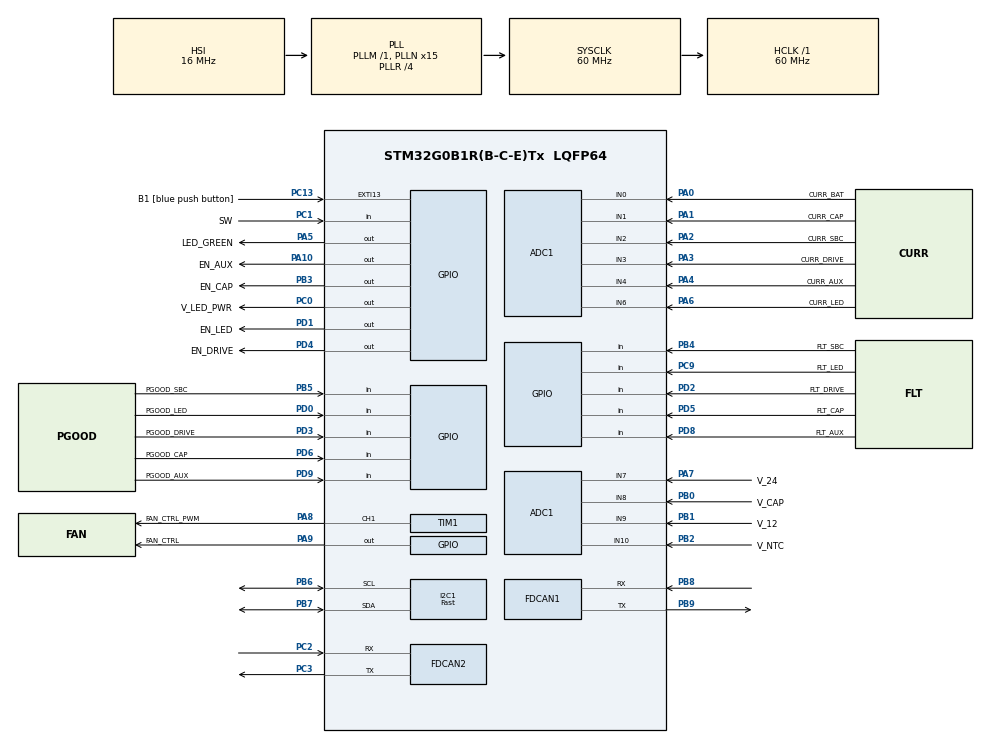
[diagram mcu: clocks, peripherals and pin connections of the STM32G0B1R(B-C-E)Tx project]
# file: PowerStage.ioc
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ADC1.ClockPrescaler=ADC_CLOCK_SYNC_PCLK_DIV4
ADC1.ContinuousConvMode=ENABLE
ADC1.DMAContinuousRequests=ENABLE
ADC1.EOCSelection=ADC_EOC_SEQ_CONV
ADC1.NbrOfConversion=1
ADC1.NbrOfConversionFlag=0
ADC1.Overrun=ADC_OVR_DATA_OVERWRITTEN
ADC1.SamplingTimeCommon1=ADC_SAMPLETIME_19CYCLES_5
ADC1.SelectedChannel=ADC_CHANNEL_0|ADC_CHANNEL_1|ADC_CHANNEL_2|ADC_CHANNEL_3|ADC_CHANNEL_4|ADC_CHANNEL_6|ADC_CHANNEL_7|ADC_CHANNEL_8|ADC_CHANNEL_9|ADC_CHANNEL_10
ADC1.Sequencer=NOT_FULLY_CONFIGURABLE
ADC1.master=1
Dma.ADC1.0.Direction=DMA_PERIPH_TO_MEMORY
Dma.ADC1.0.EventEnable=DISABLE
Dma.ADC1.0.Instance=DMA1_Channel1
Dma.ADC1.0.MemDataAlignment=DMA_MDATAALIGN_WORD
Dma.ADC1.0.MemInc=DMA_MINC_ENABLE
Dma.ADC1.0.Mode=DMA_CIRCULAR
Dma.ADC1.0.PeriphDataAlignment=DMA_PDATAALIGN_WORD
Dma.ADC1.0.PeriphInc=DMA_PINC_DISABLE
Dma.ADC1.0.Polarity=HAL_DMAMUX_REQ_GEN_RISING
Dma.ADC1.0.Priority=DMA_PRIORITY_LOW
Dma.ADC1.0.RequestNumber=1
Dma.ADC1.0.SignalID=NONE
Dma.ADC1.0.SyncEnable=DISABLE
Dma.ADC1.0.SyncPolarity=HAL_DMAMUX_SYNC_NO_EVENT
Dma.ADC1.0.SyncRequestNumber=1
Dma.ADC1.0.SyncSignalID=NONE
Dma.Request0=ADC1
FDCAN1.AutoRetransmission=ENABLE
FDCAN1.CalculateBaudRateNominal=500000
FDCAN1.CalculateTimeBitNominal=2000
FDCAN1.CalculateTimeQuantumNominal=100.0
FDCAN1.ClockDivider=FDCAN_CLOCK_DIV1
FDCAN1.DataPrescaler=1
FDCAN1.DataTimeSeg2=1
FDCAN1.ExtFiltersNbr=2
FDCAN1.NominalPrescaler=6
FDCAN1.NominalSyncJumpWidth=4
FDCAN1.NominalTimeSeg1=16
FDCAN1.NominalTimeSeg2=3
FDCAN1.StdFiltersNbr=2
FDCAN2.AutoRetransmission=ENABLE
FDCAN2.CalculateBaudRateNominal=500000
FDCAN2.CalculateTimeBitNominal=2000
FDCAN2.CalculateTimeQuantumNominal=100.0
FDCAN2.NominalPrescaler=6
FDCAN2.NominalSyncJumpWidth=4
FDCAN2.NominalTimeSeg1=16
FDCAN2.NominalTimeSeg2=3
FDCAN2.StdFiltersNbr=2
I2C1.CustomTiming=Enabled
I2C1.GeneralCallMode=I2C_GENERALCALL_DISABLE
I2C1.I2C_Speed_Mode=I2C_Fast
I2C1.Timing=0x00503D58
Mcu.Family=STM32G0
Mcu.Name=STM32G0B1R(B-C-E)Tx
Mcu.Package=LQFP64
NVIC.TIM16_FDCAN_IT0_IRQn=true\:0\:0\:false\:false\:true\:true\:true\:true
PA0.GPIO_Label=CURR_BAT
PA0.Mode=IN0
PA0.Signal=ADC1_IN0
PA1.GPIO_Label=CURR_CAP
PA1.Mode=IN1
PA1.Signal=ADC1_IN1
PA10.GPIO_Label=EN_AUX
PA10.Signal=GPIO_Output
PA13.GPIO_Label=TMS
PA13.Mode=Serial_Wire
PA13.Signal=SYS_SWDIO
PA14-BOOT0.GPIO_Label=TCK
PA14-BOOT0.Mode=Serial_Wire
PA14-BOOT0.Signal=SYS_SWCLK
PA2.GPIO_Label=CURR_SBC
PA2.Mode=IN2
PA2.Signal=ADC1_IN2
PA3.GPIO_Label=CURR_DRIVE
PA3.Mode=IN3
PA3.Signal=ADC1_IN3
PA4.GPIO_Label=CURR_AUX
PA4.Mode=IN4
PA4.Signal=ADC1_IN4
PA5.GPIO_Label=LED_GREEN
PA5.GPIO_Speed=GPIO_SPEED_FREQ_HIGH
PA5.Signal=GPIO_Output
PA6.GPIO_Label=CURR_LED
PA6.Mode=IN6
PA6.Signal=ADC1_IN6
PA7.GPIO_Label=V_24
PA7.Mode=IN7
PA7.Signal=ADC1_IN7
PA8.GPIO_Label=FAN_CTRL_PWM
PA8.PinState=GPIO_PIN_RESET
PA8.Signal=S_TIM1_CH1
PA9.GPIO_Label=FAN_CTRL
PA9.Signal=GPIO_Output
PB0.GPIO_Label=V_CAP
PB0.Mode=IN8
PB0.Signal=ADC1_IN8
PB1.GPIO_Label=V_12
PB1.Mode=IN9
PB1.Signal=ADC1_IN9
PB2.GPIO_Label=V_NTC
PB2.Mode=IN10
PB2.Signal=ADC1_IN10
PB3.GPIO_Label=EN_CAP
PB3.Signal=GPIO_Output
PB4.GPIO_Label=FLT_SBC
PB4.GPIO_PuPd=GPIO_PULLUP
PB4.Signal=GPIO_Input
PB5.GPIO_Label=PGOOD_SBC
PB5.GPIO_PuPd=GPIO_PULLUP
PB5.Signal=GPIO_Input
PB6.GPIO_Pu=GPIO_PULLUP
PB6.Mode=I2C
PB6.Signal=I2C1_SCL
PB7.GPIO_Pu=GPIO_PULLUP
PB7.Mode=I2C
PB7.Signal=I2C1_SDA
PB8.GPIO_PuPd=GPIO_PULLUP
PB8.Mode=FDCAN_Activate
PB8.Signal=FDCAN1_RX
PB9.GPIO_PuPd=GPIO_PULLUP
PB9.Mode=FDCAN_Activate
PB9.Signal=FDCAN1_TX
PC0.GPIO_Label=V_LED_PWR
PC0.Signal=GPIO_Output
PC1.GPIO_Label=SW
PC1.GPIO_PuPd=GPIO_PULLUP
PC1.Signal=GPIO_Input
PC13.GPIO_Label=B1 [blue push button]
PC13.Signal=GPXTI13
PC14-OSC32_IN\ (PC14).Mode=LSE-External-Oscillator
PC14-OSC32_IN\ (PC14).Signal=RCC_OSC32_IN
PC15-OSC32_OUT\ (PC15).Mode=LSE-External-Oscillator
PC15-OSC32_OUT\ (PC15).Signal=RCC_OSC32_OUT
PC2.GPIO_PuPd=GPIO_PULLUP
PC2.Mode=FDCAN_Activate
PC2.Signal=FDCAN2_RX
PC3.Mode=FDCAN_Activate
PC3.Signal=FDCAN2_TX
PC9.GPIO_Label=FLT_LED
PC9.GPIO_PuPd=GPIO_PULLUP
PC9.Signal=GPIO_Input
PD0.GPIO_Label=PGOOD_LED
PD0.GPIO_PuPd=GPIO_PULLUP
PD0.Signal=GPIO_Input
PD1.GPIO_Label=EN_LED
PD1.Signal=GPIO_Output
PD2.GPIO_Label=FLT_DRIVE
PD2.GPIO_PuPd=GPIO_PULLUP
PD2.Signal=GPIO_Input
PD3.GPIO_Label=PGOOD_DRIVE
PD3.GPIO_PuPd=GPIO_PULLUP
PD3.Signal=GPIO_Input
PD4.GPIO_Label=EN_DRIVE
PD4.Signal=GPIO_Output
PD5.GPIO_Label=FLT_CAP
PD5.GPIO_PuPd=GPIO_PULLUP
PD5.Signal=GPIO_Input
PD6.GPIO_Label=PGOOD_CAP
PD6.GPIO_PuPd=GPIO_PULLUP
PD6.Signal=GPIO_Input
PD8.GPIO_Label=FLT_AUX
PD8.GPIO_PuPd=GPIO_PULLUP
PD8.Signal=GPIO_Input
PD9.GPIO_Label=PGOOD_AUX
PD9.GPIO_PuPd=GPIO_PULLUP
PD9.Signal=GPIO_Input
PF0-OSC_IN\ (PF0).Mode=HSE-External-Oscillator
PF0-OSC_IN\ (PF0).Signal=RCC_OSC_IN
PF1-OSC_OUT\ (PF1).Mode=HSE-External-Oscillator
PF1-OSC_OUT\ (PF1).Signal=RCC_OSC_OUT
ProjectManager.HeapSize=0x200
ProjectManager.StackSize=0x400
ProjectManager.TargetToolchain=STM32CubeIDE
RCC.ADCFreq_Value=60000000
RCC.AHBFreq_Value=60000000
RCC.CortexFreq_Value=60000000
RCC.EXTERNAL_CLOCK_VALUE=12288000
RCC.HCLKFreq_Value=60000000
RCC.HSE_VALUE=8000000
RCC.HSI48_VALUE=48000000
RCC.HSI_VALUE=16000000
RCC.PLLN=15
RCC.PLLR=RCC_PLLR_DIV4
RCC.SYSCLKFreq_VALUE=60000000
RCC.SYSCLKSource=RCC_SYSCLKSOURCE_PLLCLK
RCC.USBFreq_Value=48000000
RCC.VCOOutputFreq_Value=240000000
SH.S_TIM1_CH1.0=TIM1_CH1,PWM Generation1 CH1
TIM1.AutoReloadPreload=TIM_AUTORELOAD_PRELOAD_ENABLE
TIM1.Channel-PWM\ Generation1\ CH1=TIM_CHANNEL_1
TIM1.OCIdleState_1=TIM_OCIDLESTATE_RESET
TIM1.OCPolarity_1=TIM_OCPOLARITY_HIGH
TIM1.Period=999
TIM1.Prescaler=59
TIM1.Pulse-PWM\ Generation1\ CH1=100
VP_SYS_VS_DBSignals.Mode=DisableDeadBatterySignals
VP_TIM1_VS_ClockSourceINT.Mode=Internal
board=NUCLEO-G0B1RE

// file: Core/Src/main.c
/* USER CODE BEGIN Header */
/**
  ******************************************************************************
  * @file           : main.c
  * @brief          : Main program body
  ******************************************************************************
  * @attention
  *
  * Copyright (c) 2026 STMicroelectronics.
  * All rights reserved.
  *
  * This software is licensed under terms that can be found in the LICENSE file
  * in the root directory of this software component.
  * If no LICENSE file comes with this software, it is provided AS-IS.
  *
  ******************************************************************************
  */
/* USER CODE END Header */
#include "main.h"

/* USER CODE BEGIN Includes */

#include "powerstage_app.h"
#include "io_module.h"
/* USER CODE END Includes */

/* USER CODE BEGIN PTD */

/**
  * @brief  Vector base address configuration. It should no longer be at the start of
  *         flash memory but moved forward because the first part of flash is
  *         reserved for the bootloader. Note that this is already done by the
  *         bootloader before starting this program. Unfortunately, function
  *         SystemInit() overwrites this change again.
  * @return none.
  */
static void VectorBase_Config(void)
{
  /* The constant array with vectors of the vector table is declared externally in the
   * c-startup code.
   */
  extern const unsigned long g_pfnVectors[];

  /* Remap the vector table to where the vector table is located for this program. */
  SCB->VTOR = (unsigned long)&g_pfnVectors[0];
}
/* USER CODE END PTD */

ADC_HandleTypeDef hadc1;
DMA_HandleTypeDef hdma_adc1;

FDCAN_HandleTypeDef hfdcan1;
FDCAN_HandleTypeDef hfdcan2;

I2C_HandleTypeDef hi2c1;

TIM_HandleTypeDef htim1;

void SystemClock_Config(void);
static void MX_GPIO_Init(void);
static void MX_DMA_Init(void);
static void MX_ADC1_Init(void);
static void MX_FDCAN1_Init(void);
static void MX_FDCAN2_Init(void);
static void MX_I2C1_Init(void);
static void MX_TIM1_Init(void);

int main(void)
{

  /* USER CODE BEGIN 1 */
 VectorBase_Config();
  /* USER CODE END 1 */

  /* MCU Configuration--------------------------------------------------------*/

  /* Reset of all peripherals, Initializes the Flash interface and the Systick. */
  HAL_Init();

  /* Configure the system clock */
  SystemClock_Config();

  /* Initialize all configured peripherals */
  MX_GPIO_Init();
  MX_DMA_Init();
  MX_ADC1_Init();
  MX_FDCAN1_Init();
  MX_FDCAN2_Init();
  MX_I2C1_Init();
  MX_TIM1_Init();
  /* USER CODE BEGIN 2 */
//  AppInit();        /* OpenBLT bootloader hook */
  PS_App_Init();    /* PowerStage: CAN TX header init (full init deferred to first task call) */
  HS_DisableAll();
  /* USER CODE END 2 */

  /* Infinite loop */
  while (1)
  {

    /* USER CODE BEGIN 3 */
//    AppTask();        /* OpenBLT bootloader hook */
    PS_App_Task();    /* PowerStage state machine: Init → Running ↔ Fault */
  }
  /* USER CODE END 3 */
}

void SystemClock_Config(void)
{
  RCC_OscInitTypeDef RCC_OscInitStruct = {0};
  RCC_ClkInitTypeDef RCC_ClkInitStruct = {0};

  /** Configure the main internal regulator output voltage
  */
  HAL_PWREx_ControlVoltageScaling(PWR_REGULATOR_VOLTAGE_SCALE1);

  /** Initializes the RCC Oscillators according to the specified parameters
  * in the RCC_OscInitTypeDef structure.
  */
  RCC_OscInitStruct.OscillatorType = RCC_OSCILLATORTYPE_HSI;
  RCC_OscInitStruct.HSIState = RCC_HSI_ON;
  RCC_OscInitStruct.HSIDiv = RCC_HSI_DIV1;
  RCC_OscInitStruct.HSICalibrationValue = RCC_HSICALIBRATION_DEFAULT;
  RCC_OscInitStruct.PLL.PLLState = RCC_PLL_ON;
  RCC_OscInitStruct.PLL.PLLSource = RCC_PLLSOURCE_HSI;
  RCC_OscInitStruct.PLL.PLLM = RCC_PLLM_DIV1;
  RCC_OscInitStruct.PLL.PLLN = 15;
  RCC_OscInitStruct.PLL.PLLP = RCC_PLLP_DIV2;
  RCC_OscInitStruct.PLL.PLLQ = RCC_PLLQ_DIV2;
  RCC_OscInitStruct.PLL.PLLR = RCC_PLLR_DIV4;
  if (HAL_RCC_OscConfig(&RCC_OscInitStruct) != HAL_OK)
  {
    Error_Handler();
  }

  /** Initializes the CPU, AHB and APB buses clocks
  */
  RCC_ClkInitStruct.ClockType = RCC_CLOCKTYPE_HCLK|RCC_CLOCKTYPE_SYSCLK
                              |RCC_CLOCKTYPE_PCLK1;
  RCC_ClkInitStruct.SYSCLKSource = RCC_SYSCLKSOURCE_PLLCLK;
  RCC_ClkInitStruct.AHBCLKDivider = RCC_SYSCLK_DIV1;
  RCC_ClkInitStruct.APB1CLKDivider = RCC_HCLK_DIV1;

  if (HAL_RCC_ClockConfig(&RCC_ClkInitStruct, FLASH_LATENCY_2) != HAL_OK)
  {
    Error_Handler();
  }
}

static void MX_ADC1_Init(void)
{

  ADC_ChannelConfTypeDef sConfig = {0};

  /** Configure the global features of the ADC (Clock, Resolution, Data Alignment and number of conversion)
  */
  hadc1.Instance = ADC1;
  hadc1.Init.ClockPrescaler = ADC_CLOCK_SYNC_PCLK_DIV4;
  hadc1.Init.Resolution = ADC_RESOLUTION_12B;
  hadc1.Init.DataAlign = ADC_DATAALIGN_RIGHT;
  hadc1.Init.ScanConvMode = ADC_SCAN_SEQ_FIXED;
  hadc1.Init.EOCSelection = ADC_EOC_SEQ_CONV;
  hadc1.Init.LowPowerAutoWait = DISABLE;
  hadc1.Init.LowPowerAutoPowerOff = DISABLE;
  hadc1.Init.ContinuousConvMode = ENABLE;
  hadc1.Init.NbrOfConversion = 1;
  hadc1.Init.ExternalTrigConv = ADC_SOFTWARE_START;
  hadc1.Init.ExternalTrigConvEdge = ADC_EXTERNALTRIGCONVEDGE_NONE;
  hadc1.Init.DMAContinuousRequests = ENABLE;
  hadc1.Init.Overrun = ADC_OVR_DATA_OVERWRITTEN;
  hadc1.Init.SamplingTimeCommon1 = ADC_SAMPLETIME_19CYCLES_5;
  hadc1.Init.OversamplingMode = DISABLE;
  hadc1.Init.TriggerFrequencyMode = ADC_TRIGGER_FREQ_HIGH;
  if (HAL_ADC_Init(&hadc1) != HAL_OK)
  {
    Error_Handler();
  }

  /** Configure Regular Channel
  */
  sConfig.Channel = ADC_CHANNEL_0;
  sConfig.Rank = ADC_RANK_CHANNEL_NUMBER;
  if (HAL_ADC_ConfigChannel(&hadc1, &sConfig) != HAL_OK)
  {
    Error_Handler();
  }

  /** Configure Regular Channel
  */
  sConfig.Channel = ADC_CHANNEL_1;
  if (HAL_ADC_ConfigChannel(&hadc1, &sConfig) != HAL_OK)
  {
    Error_Handler();
  }

  /** Configure Regular Channel
  */
  sConfig.Channel = ADC_CHANNEL_2;
  if (HAL_ADC_ConfigChannel(&hadc1, &sConfig) != HAL_OK)
  {
    Error_Handler();
  }

  /** Configure Regular Channel
  */
  sConfig.Channel = ADC_CHANNEL_3;
  if (HAL_ADC_ConfigChannel(&hadc1, &sConfig) != HAL_OK)
  {
    Error_Handler();
  }

  /** Configure Regular Channel
  */
  sConfig.Channel = ADC_CHANNEL_4;
  if (HAL_ADC_ConfigChannel(&hadc1, &sConfig) != HAL_OK)
  {
    Error_Handler();
  }

  /** Configure Regular Channel
  */
  sConfig.Channel = ADC_CHANNEL_6;
  if (HAL_ADC_ConfigChannel(&hadc1, &sConfig) != HAL_OK)
  {
    Error_Handler();
  }

  /** Configure Regular Channel
  */
  sConfig.Channel = ADC_CHANNEL_7;
  if (HAL_ADC_ConfigChannel(&hadc1, &sConfig) != HAL_OK)
  {
    Error_Handler();
  }

  /** Configure Regular Channel
  */
  sConfig.Channel = ADC_CHANNEL_8;
  if (HAL_ADC_ConfigChannel(&hadc1, &sConfig) != HAL_OK)
  {
    Error_Handler();
  }

  /** Configure Regular Channel
  */
  sConfig.Channel = ADC_CHANNEL_9;
  if (HAL_ADC_ConfigChannel(&hadc1, &sConfig) != HAL_OK)
  {
    Error_Handler();
  }

  /** Configure Regular Channel
  */
  sConfig.Channel = ADC_CHANNEL_10;
  if (HAL_ADC_ConfigChannel(&hadc1, &sConfig) != HAL_OK)
  {
    Error_Handler();
  }
  /* USER CODE BEGIN ADC1_Init 2 */
  if (HAL_ADCEx_Calibration_Start(&hadc1) != HAL_OK)
  {
      Error_Handler();
  }
  /* USER CODE END ADC1_Init 2 */

}

static void MX_FDCAN1_Init(void)
{

  hfdcan1.Instance = FDCAN1;
  hfdcan1.Init.ClockDivider = FDCAN_CLOCK_DIV1;
  hfdcan1.Init.FrameFormat = FDCAN_FRAME_CLASSIC;
  hfdcan1.Init.Mode = FDCAN_MODE_NORMAL;
  hfdcan1.Init.AutoRetransmission = ENABLE;
  hfdcan1.Init.TransmitPause = DISABLE;
  hfdcan1.Init.ProtocolException = DISABLE;
  hfdcan1.Init.NominalPrescaler = 6;
  hfdcan1.Init.NominalSyncJumpWidth = 4;
  hfdcan1.Init.NominalTimeSeg1 = 16;
  hfdcan1.Init.NominalTimeSeg2 = 3;
  hfdcan1.Init.DataPrescaler = 1;
  hfdcan1.Init.DataSyncJumpWidth = 1;
  hfdcan1.Init.DataTimeSeg1 = 1;
  hfdcan1.Init.DataTimeSeg2 = 1;
  hfdcan1.Init.StdFiltersNbr = 2;
  hfdcan1.Init.ExtFiltersNbr = 2;
  hfdcan1.Init.TxFifoQueueMode = FDCAN_TX_FIFO_OPERATION;
  if (HAL_FDCAN_Init(&hfdcan1) != HAL_OK)
  {
    Error_Handler();
  }

}

static void MX_FDCAN2_Init(void)
{

  hfdcan2.Instance = FDCAN2;
  hfdcan2.Init.ClockDivider = FDCAN_CLOCK_DIV1;
  hfdcan2.Init.FrameFormat = FDCAN_FRAME_CLASSIC;
  hfdcan2.Init.Mode = FDCAN_MODE_NORMAL;
  hfdcan2.Init.AutoRetransmission = ENABLE;
  hfdcan2.Init.TransmitPause = DISABLE;
  hfdcan2.Init.ProtocolException = DISABLE;
  hfdcan2.Init.NominalPrescaler = 6;
  hfdcan2.Init.NominalSyncJumpWidth = 4;
  hfdcan2.Init.NominalTimeSeg1 = 16;
  hfdcan2.Init.NominalTimeSeg2 = 3;
  hfdcan2.Init.DataPrescaler = 1;
  hfdcan2.Init.DataSyncJumpWidth = 1;
  hfdcan2.Init.DataTimeSeg1 = 1;
  hfdcan2.Init.DataTimeSeg2 = 1;
  hfdcan2.Init.StdFiltersNbr = 2;
  hfdcan2.Init.ExtFiltersNbr = 0;
  hfdcan2.Init.TxFifoQueueMode = FDCAN_TX_FIFO_OPERATION;
  if (HAL_FDCAN_Init(&hfdcan2) != HAL_OK)
  {
    Error_Handler();
  }

}

static void MX_I2C1_Init(void)
{

  hi2c1.Instance = I2C1;
  hi2c1.Init.Timing = 0x00503D58;
  hi2c1.Init.OwnAddress1 = 0;
  hi2c1.Init.AddressingMode = I2C_ADDRESSINGMODE_7BIT;
  hi2c1.Init.DualAddressMode = I2C_DUALADDRESS_DISABLE;
  hi2c1.Init.OwnAddress2 = 0;
  hi2c1.Init.OwnAddress2Masks = I2C_OA2_NOMASK;
  hi2c1.Init.GeneralCallMode = I2C_GENERALCALL_DISABLE;
  hi2c1.Init.NoStretchMode = I2C_NOSTRETCH_DISABLE;
  if (HAL_I2C_Init(&hi2c1) != HAL_OK)
  {
    Error_Handler();
  }

  /** Configure Analogue filter
  */
  if (HAL_I2CEx_ConfigAnalogFilter(&hi2c1, I2C_ANALOGFILTER_ENABLE) != HAL_OK)
  {
    Error_Handler();
  }

  /** Configure Digital filter
  */
  if (HAL_I2CEx_ConfigDigitalFilter(&hi2c1, 0) != HAL_OK)
  {
    Error_Handler();
  }
  /* USER CODE BEGIN I2C1_Init 2 */
//	I2C1->CR1 |= (I2C_CR1_TXIE | I2C_CR1_RXIE | I2C_CR1_ERRIE);
//	HAL_NVIC_SetPriority(I2C1_IRQn, 3, 0);
//	HAL_NVIC_EnableIRQ(I2C1_IRQn);

  /* USER CODE END I2C1_Init 2 */

}

static void MX_TIM1_Init(void)
{

  TIM_ClockConfigTypeDef sClockSourceConfig = {0};
  TIM_MasterConfigTypeDef sMasterConfig = {0};
  TIM_OC_InitTypeDef sConfigOC = {0};
  TIM_BreakDeadTimeConfigTypeDef sBreakDeadTimeConfig = {0};

  htim1.Instance = TIM1;
  htim1.Init.Prescaler = 59;
  htim1.Init.CounterMode = TIM_COUNTERMODE_UP;
  htim1.Init.Period = 999;
  htim1.Init.ClockDivision = TIM_CLOCKDIVISION_DIV1;
  htim1.Init.RepetitionCounter = 0;
  htim1.Init.AutoReloadPreload = TIM_AUTORELOAD_PRELOAD_ENABLE;
  if (HAL_TIM_Base_Init(&htim1) != HAL_OK)
  {
    Error_Handler();
  }
  sClockSourceConfig.ClockSource = TIM_CLOCKSOURCE_INTERNAL;
  if (HAL_TIM_ConfigClockSource(&htim1, &sClockSourceConfig) != HAL_OK)
  {
    Error_Handler();
  }
  if (HAL_TIM_PWM_Init(&htim1) != HAL_OK)
  {
    Error_Handler();
  }
  sMasterConfig.MasterOutputTrigger = TIM_TRGO_RESET;
  sMasterConfig.MasterOutputTrigger2 = TIM_TRGO2_RESET;
  sMasterConfig.MasterSlaveMode = TIM_MASTERSLAVEMODE_DISABLE;
  if (HAL_TIMEx_MasterConfigSynchronization(&htim1, &sMasterConfig) != HAL_OK)
  {
    Error_Handler();
  }
  sConfigOC.OCMode = TIM_OCMODE_PWM1;
  sConfigOC.Pulse = 100;
  sConfigOC.OCPolarity = TIM_OCPOLARITY_HIGH;
  sConfigOC.OCNPolarity = TIM_OCNPOLARITY_HIGH;
  sConfigOC.OCFastMode = TIM_OCFAST_DISABLE;
  sConfigOC.OCIdleState = TIM_OCIDLESTATE_RESET;
  sConfigOC.OCNIdleState = TIM_OCNIDLESTATE_RESET;
  if (HAL_TIM_PWM_ConfigChannel(&htim1, &sConfigOC, TIM_CHANNEL_1) != HAL_OK)
  {
    Error_Handler();
  }
  sBreakDeadTimeConfig.OffStateRunMode = TIM_OSSR_DISABLE;
  sBreakDeadTimeConfig.OffStateIDLEMode = TIM_OSSI_DISABLE;
  sBreakDeadTimeConfig.LockLevel = TIM_LOCKLEVEL_OFF;
  sBreakDeadTimeConfig.DeadTime = 0;
  sBreakDeadTimeConfig.BreakState = TIM_BREAK_DISABLE;
  sBreakDeadTimeConfig.BreakPolarity = TIM_BREAKPOLARITY_HIGH;
  sBreakDeadTimeConfig.BreakFilter = 0;
  sBreakDeadTimeConfig.BreakAFMode = TIM_BREAK_AFMODE_INPUT;
  sBreakDeadTimeConfig.Break2State = TIM_BREAK2_DISABLE;
  sBreakDeadTimeConfig.Break2Polarity = TIM_BREAK2POLARITY_HIGH;
  sBreakDeadTimeConfig.Break2Filter = 0;
  sBreakDeadTimeConfig.Break2AFMode = TIM_BREAK_AFMODE_INPUT;
  sBreakDeadTimeConfig.AutomaticOutput = TIM_AUTOMATICOUTPUT_DISABLE;
  if (HAL_TIMEx_ConfigBreakDeadTime(&htim1, &sBreakDeadTimeConfig) != HAL_OK)
  {
    Error_Handler();
  }
  HAL_TIM_MspPostInit(&htim1);

}

static void MX_DMA_Init(void)
{

  /* DMA controller clock enable */
  __HAL_RCC_DMA1_CLK_ENABLE();

}

static void MX_GPIO_Init(void)
{
  GPIO_InitTypeDef GPIO_InitStruct = {0};

  /* GPIO Ports Clock Enable */
  __HAL_RCC_GPIOC_CLK_ENABLE();
  __HAL_RCC_GPIOF_CLK_ENABLE();
  __HAL_RCC_GPIOA_CLK_ENABLE();
  __HAL_RCC_GPIOB_CLK_ENABLE();
  __HAL_RCC_GPIOD_CLK_ENABLE();

  /*Configure GPIO pin Output Level */
  HAL_GPIO_WritePin(V_LED_PWR_GPIO_Port, V_LED_PWR_Pin, GPIO_PIN_RESET);

  /*Configure GPIO pin Output Level */
  HAL_GPIO_WritePin(GPIOA, LED_GREEN_Pin|FAN_CTRL_Pin|EN_AUX_Pin, GPIO_PIN_RESET);

  /*Configure GPIO pin Output Level */
  HAL_GPIO_WritePin(GPIOD, EN_LED_Pin|EN_DRIVE_Pin, GPIO_PIN_RESET);

  /*Configure GPIO pin Output Level */
  HAL_GPIO_WritePin(EN_CAP_GPIO_Port, EN_CAP_Pin, GPIO_PIN_RESET);

  /*Configure GPIO pin : B1_Pin */
  GPIO_InitStruct.Pin = B1_Pin;
  GPIO_InitStruct.Mode = GPIO_MODE_IT_RISING;
  GPIO_InitStruct.Pull = GPIO_NOPULL;
  HAL_GPIO_Init(B1_GPIO_Port, &GPIO_InitStruct);

  /*Configure GPIO pin : V_LED_PWR_Pin */
  GPIO_InitStruct.Pin = V_LED_PWR_Pin;
  GPIO_InitStruct.Mode = GPIO_MODE_OUTPUT_PP;
  GPIO_InitStruct.Pull = GPIO_NOPULL;
  GPIO_InitStruct.Speed = GPIO_SPEED_FREQ_LOW;
  HAL_GPIO_Init(V_LED_PWR_GPIO_Port, &GPIO_InitStruct);

  /*Configure GPIO pins : SW_Pin FLT_LED_Pin */
  GPIO_InitStruct.Pin = SW_Pin|FLT_LED_Pin;
  GPIO_InitStruct.Mode = GPIO_MODE_INPUT;
  GPIO_InitStruct.Pull = GPIO_PULLUP;
  HAL_GPIO_Init(GPIOC, &GPIO_InitStruct);

  /*Configure GPIO pin : LED_GREEN_Pin */
  GPIO_InitStruct.Pin = LED_GREEN_Pin;
  GPIO_InitStruct.Mode = GPIO_MODE_OUTPUT_PP;
  GPIO_InitStruct.Pull = GPIO_NOPULL;
  GPIO_InitStruct.Speed = GPIO_SPEED_FREQ_HIGH;
  HAL_GPIO_Init(LED_GREEN_GPIO_Port, &GPIO_InitStruct);

  /*Configure GPIO pins : FAN_CTRL_Pin EN_AUX_Pin */
  GPIO_InitStruct.Pin = FAN_CTRL_Pin|EN_AUX_Pin;
  GPIO_InitStruct.Mode = GPIO_MODE_OUTPUT_PP;
  GPIO_InitStruct.Pull = GPIO_NOPULL;
  GPIO_InitStruct.Speed = GPIO_SPEED_FREQ_LOW;
  HAL_GPIO_Init(GPIOA, &GPIO_InitStruct);

  /*Configure GPIO pins : FLT_AUX_Pin PGOOD_AUX_Pin PGOOD_LED_Pin FLT_DRIVE_Pin
                           PGOOD_DRIVE_Pin FLT_CAP_Pin PGOOD_CAP_Pin */
  GPIO_InitStruct.Pin = FLT_AUX_Pin|PGOOD_AUX_Pin|PGOOD_LED_Pin|FLT_DRIVE_Pin
                          |PGOOD_DRIVE_Pin|FLT_CAP_Pin|PGOOD_CAP_Pin;
  GPIO_InitStruct.Mode = GPIO_MODE_INPUT;
  GPIO_InitStruct.Pull = GPIO_PULLUP;
  HAL_GPIO_Init(GPIOD, &GPIO_InitStruct);

  /*Configure GPIO pins : EN_LED_Pin EN_DRIVE_Pin */
  GPIO_InitStruct.Pin = EN_LED_Pin|EN_DRIVE_Pin;
  GPIO_InitStruct.Mode = GPIO_MODE_OUTPUT_PP;
  GPIO_InitStruct.Pull = GPIO_NOPULL;
  GPIO_InitStruct.Speed = GPIO_SPEED_FREQ_LOW;
  HAL_GPIO_Init(GPIOD, &GPIO_InitStruct);

  /*Configure GPIO pin : EN_CAP_Pin */
  GPIO_InitStruct.Pin = EN_CAP_Pin;
  GPIO_InitStruct.Mode = GPIO_MODE_OUTPUT_PP;
  GPIO_InitStruct.Pull = GPIO_NOPULL;
  GPIO_InitStruct.Speed = GPIO_SPEED_FREQ_LOW;
  HAL_GPIO_Init(EN_CAP_GPIO_Port, &GPIO_InitStruct);

  /*Configure GPIO pins : FLT_SBC_Pin PGOOD_SBC_Pin */
  GPIO_InitStruct.Pin = FLT_SBC_Pin|PGOOD_SBC_Pin;
  GPIO_InitStruct.Mode = GPIO_MODE_INPUT;
  GPIO_InitStruct.Pull = GPIO_PULLUP;
  HAL_GPIO_Init(GPIOB, &GPIO_InitStruct);

}

void Error_Handler(void)
{
  __disable_irq();
  while (1)
  {
  }
}
